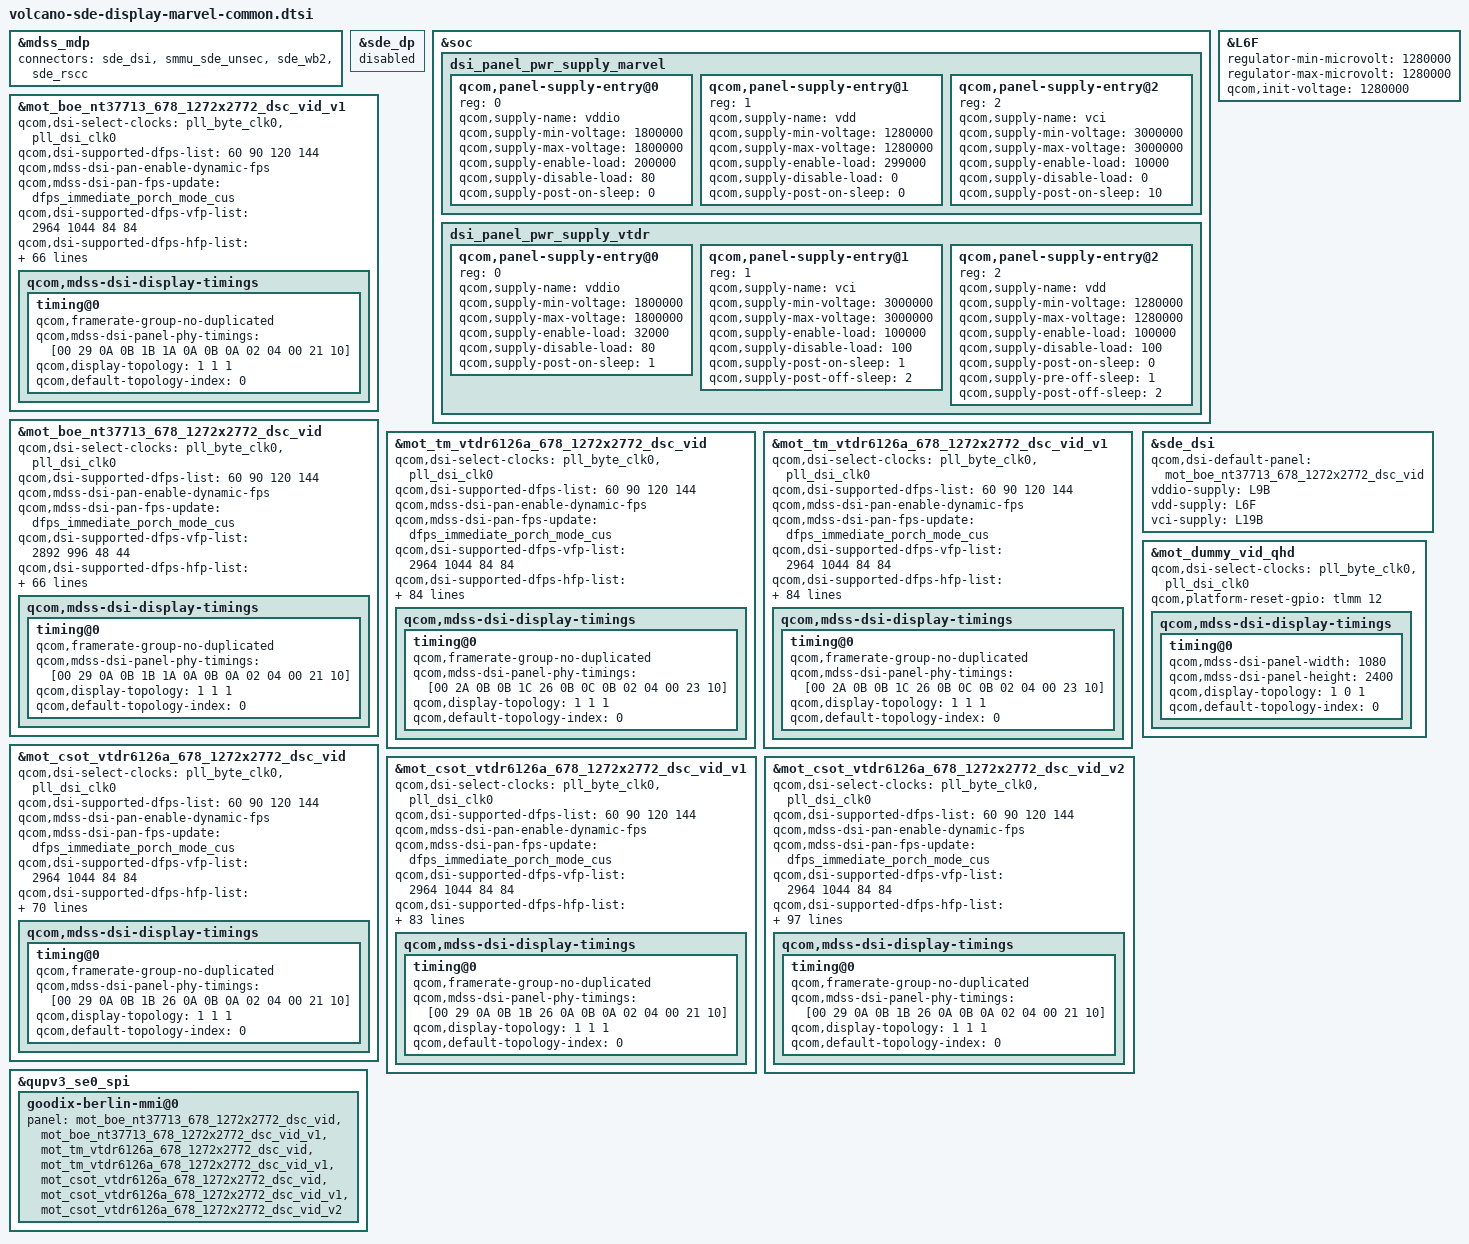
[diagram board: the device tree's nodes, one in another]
#include "volcano-sde-display.dtsi"
#include "dsi-panel-mot-dummy-qhd-video.dtsi"
#include "dsi-panel-mot-boe-nt37713-678_1272x2772-dsc-video-144hz-common.dtsi"
#include "dsi-panel-mot-boe-nt37713-678_1272x2772-dsc-video-144hz-common-v1.dtsi"
#include "dsi-panel-mot-tm-vtdr6126a-678_1272x2772-dsc-video-144hz-common.dtsi"
#include "dsi-panel-mot-tm-vtdr6126a-678_1272x2772-dsc-video-144hz-common-lhbm.dtsi"
#include "dsi-panel-mot-tm-vtdr6126a-678_1272x2772-dsc-video-144hz-common_v1.dtsi"
#include "dsi-panel-mot-tm-vtdr6126a-678_1272x2772-dsc-video-144hz-common-lhbm-v1.dtsi"
#include "dsi-panel-mot-csot-vtdr6126a-678_1272x2772-dsc-video-144hz-common.dtsi"
#include "dsi-panel-mot-csot-vtdr6126a-678_1272x2772-dsc-video-144hz-common-lhbm.dtsi"
#include "dsi-panel-mot-csot-vtdr6126a-678_1272x2772-dsc-video-144hz-common_v1.dtsi"
#include "dsi-panel-mot-csot-vtdr6126a-678_1272x2772-dsc-video-144hz-common-lhbm-v1.dtsi"
#include "dsi-panel-mot-csot-vtdr6126a-678_1272x2772-dsc-video-144hz-common_v2.dtsi"
#include "dsi-panel-mot-csot-vtdr6126a-678_1272x2772-dsc-video-144hz-common-lhbm-v2.dtsi"

&mdss_mdp {
	connectors = <&sde_dsi &smmu_sde_unsec &sde_wb2 &sde_rscc>;
};

&sde_dp {
	status = "disabled";
};

&soc {
	dsi_panel_pwr_supply_marvel: dsi_panel_pwr_supply_marvel {
		#address-cells = <1>;
		#size-cells = <0>;

		qcom,panel-supply-entry@0 {
			reg = <0>;
			qcom,supply-name = "vddio";
			qcom,supply-min-voltage = <1800000>;
			qcom,supply-max-voltage = <1800000>;
			qcom,supply-enable-load = <200000>;
			qcom,supply-disable-load = <80>;
			qcom,supply-post-on-sleep = <0>;
		};

		qcom,panel-supply-entry@1 {
			reg = <1>;
			qcom,supply-name = "vdd";
			qcom,supply-min-voltage = <1280000>;
			qcom,supply-max-voltage = <1280000>;
			qcom,supply-enable-load = <299000>;
			qcom,supply-disable-load = <0>;
			qcom,supply-post-on-sleep = <0>;
		};

		qcom,panel-supply-entry@2 {
			reg = <2>;
			qcom,supply-name = "vci";
			qcom,supply-min-voltage = <3000000>;
			qcom,supply-max-voltage = <3000000>;
			qcom,supply-enable-load = <10000>;
			qcom,supply-disable-load = <0>;
			qcom,supply-post-on-sleep = <10>;
		};
	};

	dsi_panel_pwr_supply_vtdr: dsi_panel_pwr_supply_vtdr {
		#address-cells = <1>;
		#size-cells = <0>;
		qcom,panel-supply-entry@0 {
			reg = <0>;
			qcom,supply-name = "vddio";
			qcom,supply-min-voltage = <1800000>;
			qcom,supply-max-voltage = <1800000>;
			qcom,supply-enable-load = <32000>;
			qcom,supply-disable-load = <80>;
			qcom,supply-post-on-sleep = <1>;
		};

		qcom,panel-supply-entry@1 {
			reg = <1>;
			qcom,supply-name = "vci";
			qcom,supply-min-voltage = <3000000>;
			qcom,supply-max-voltage = <3000000>;
			qcom,supply-enable-load = <100000>;
			qcom,supply-disable-load = <100>;
			qcom,supply-post-on-sleep = <1>;
			qcom,supply-post-off-sleep = <2>;
		};

		qcom,panel-supply-entry@2 {
			reg = <2>;
			qcom,supply-name = "vdd";
			qcom,supply-min-voltage = <1280000>;
			qcom,supply-max-voltage = <1280000>;
			qcom,supply-enable-load = <100000>;
			qcom,supply-disable-load = <100>;
			qcom,supply-post-on-sleep = <0>;
			qcom,supply-pre-off-sleep = <1>;
			qcom,supply-post-off-sleep = <2>;
		};
	};
};

&mot_boe_nt37713_678_1272x2772_dsc_vid_v1 {
	qcom,dsi-select-clocks = "pll_byte_clk0", "pll_dsi_clk0";

	qcom,dsi-supported-dfps-list = <60 90 120 144>;
	qcom,mdss-dsi-pan-enable-dynamic-fps;
	qcom,mdss-dsi-pan-fps-update = "dfps_immediate_porch_mode_cus";
	qcom,dsi-supported-dfps-vfp-list = <2964 1044 84 84>;
	qcom,dsi-supported-dfps-hfp-list = <108 108 108 28>;
	qcom,mdss-dsi-pan-dfps-send-command;
	qcom,dsi-supported-dfps-cmd-delay-effect-list = <144 120>;

	qcom,panel-supply-entries = <&dsi_panel_pwr_supply_marvel>;
	qcom,mdss-dsi-no-panel-on-read-support;
	qcom,mdss-dsi-bl-pmic-control-type = "bl_ctrl_dcs";
	qcom,mdss-dsi-bl-min-level = <420>;//
	qcom,mdss-dsi-bl-max-level = <16153>;
	qcom,mdss-dsi-bl-default-level = <6735>;
	qcom,mdss-brightness-max-level = <16153>;
	qcom,platform-reset-gpio = <&tlmm 12 0>;

	qcom,mdss-dsi-bl-inverted-dbv;
	qcom,mdss-dsi-bl-is-exponent;

	qcom,mdss-dsi-panel-hdr-enabled;//
	qcom,mdss-dsi-panel-hdr-color-primaries = <14950 15750 34000
	        16000 13000 35500 7000 2500>;
	qcom,mdss-dsi-panel-peak-brightness = <15000000>;
	qcom,mdss-dsi-panel-blackness-level = <1>;

	qcom,mdss-dsi-panel-status-check-mode = "reg_read";
	qcom,mdss-dsi-panel-status-command = [06 01 00 01 00 00 01 0A];
	qcom,mdss-dsi-panel-status-command-state = "dsi_lp_mode";
	qcom,mdss-dsi-panel-status-value = <0x9C>;
	qcom,mdss-dsi-panel-status-read-length = <1>;
	qcom,esd-check-enabled;

	qcom,cellid-read-enabled;//
	qcom,mdss-dsi-panel-cellid-read-length = <23>;
	qcom,mdss-dsi-panel-cellid-command = [06 01 00 01 00 00 01 AC];
	qcom,mdss-dsi-panel-cellid-command-state = "dsi_lp_mode";

	qcom,check_pcd;
	qcom,pcd-reg-read-enabled;
	qcom,pcd-reg-check-before-read;
	qcom,mdss-dsi-panel-pcd-reg-read-length = <3>;
	qcom,mdss-dsi-panel-pcd-reg-offset = <1>;
	qcom,mdss-dsi-panel-pcd-reg-mask = <0xFFFF>;
	qcom,mdss-dsi-panel-pcd-reg-command = [
		39 00 00 40 00 00 06 F0 55 AA 52 08 01
		06 01 00 01 00 00 01 D0];
	qcom,mdss-dsi-panel-pcd-value-2bytes;
	qcom,mdss-dsi-panel-pcd-reg-pass-min = <0x0200>;
	qcom,mdss-dsi-panel-pcd-reg-pass-max = <0x02C0>;
	qcom,mdss-dsi-panel-pcd-reg-read-delay-ms = <150>;
	qcom,mdss-dsi-panel-pcd-reg-seq-interval = <30>; //pcd reg read seq interval per screen on.
	qcom,mdss-dsi-panel-pcd-check-time-interval-in-minutes = <480>; //480 minutes/8hours for pcd reg read time interval

	// only parse for cmd panel
	qcom,mdss-dsi-te-pin-select = <1>;
	qcom,mdss-dsi-te-dcs-command = <1>;
	qcom,mdss-dsi-te-using-te-pin;
	qcom,mdss-dsi-te-check-enable;

	//AOD: config switch mode
	qcom,mdss-dsi-panel-mode-switch;
	//qcom,poms-align-panel-vsync;
	qcom,dynamic-mode-switch-enabled;
	//qcom,dynamic-mode-switch-type = "dynamic-switch-immediate";

	qcom,mdss-dsi-panel-AOD-config-enabled;
	qcom,mdss-dsi-panel-AOD-bl-vid-update;

	qcom,mdss-dsi-panel-AOD-THRESHOLD-min-nit = <1112>;	//5nit
	qcom,mdss-dsi-panel-AOD-THRESHOLD-hig-nit = <6735>;	//160nit

	qcom,mdss-dsi-panel-AOD-bl-min = <16>;   //0x0010, <5nit
	qcom,mdss-dsi-panel-AOD-bl-mid = <11344>;   //0x2C50, 5-160nit
	qcom,mdss-dsi-panel-AOD-bl-hig = <16000>;   //0x3E80, >160nit

	qcom,mdss-dsi-display-timings {
		timing@0 {
			qcom,framerate-group-no-duplicated;
			qcom,mdss-dsi-panel-phy-timings = [00 29 0A 0B 1B 1A 0A
				0B 0A 02 04 00 21 10];
			qcom,display-topology = <1 1 1>;
			qcom,default-topology-index = <0>;
		};
	};
};

&mot_boe_nt37713_678_1272x2772_dsc_vid {
	qcom,dsi-select-clocks = "pll_byte_clk0", "pll_dsi_clk0";

	qcom,dsi-supported-dfps-list = <60 90 120 144>;
	qcom,mdss-dsi-pan-enable-dynamic-fps;
	qcom,mdss-dsi-pan-fps-update = "dfps_immediate_porch_mode_cus";
	qcom,dsi-supported-dfps-vfp-list = <2892 996 48 44>;
	qcom,dsi-supported-dfps-hfp-list = <108 108 108 28>;
	qcom,mdss-dsi-pan-dfps-send-command;
	qcom,dsi-supported-dfps-cmd-delay-effect-list = <144 120>;

	qcom,panel-supply-entries = <&dsi_panel_pwr_supply_marvel>;
	qcom,mdss-dsi-no-panel-on-read-support;
	qcom,mdss-dsi-bl-pmic-control-type = "bl_ctrl_dcs";
	qcom,mdss-dsi-bl-min-level = <420>;//
	qcom,mdss-dsi-bl-max-level = <16153>;
	qcom,mdss-dsi-bl-default-level = <6735>;
	qcom,mdss-brightness-max-level = <16153>;
	qcom,platform-reset-gpio = <&tlmm 12 0>;

	qcom,mdss-dsi-bl-inverted-dbv;
	qcom,mdss-dsi-bl-is-exponent;

	qcom,mdss-dsi-panel-hdr-enabled;//
	qcom,mdss-dsi-panel-hdr-color-primaries = <14950 15750 34000
	        16000 13000 35500 7000 2500>;
	qcom,mdss-dsi-panel-peak-brightness = <15000000>;
	qcom,mdss-dsi-panel-blackness-level = <1>;

	qcom,mdss-dsi-panel-status-check-mode = "reg_read";
	qcom,mdss-dsi-panel-status-command = [06 01 00 01 00 00 01 0A];
	qcom,mdss-dsi-panel-status-command-state = "dsi_lp_mode";
	qcom,mdss-dsi-panel-status-value = <0x9C>;
	qcom,mdss-dsi-panel-status-read-length = <1>;
	qcom,esd-check-enabled;

	qcom,cellid-read-enabled;//
	qcom,mdss-dsi-panel-cellid-read-length = <23>;
	qcom,mdss-dsi-panel-cellid-command = [06 01 00 01 00 00 01 AC];
	qcom,mdss-dsi-panel-cellid-command-state = "dsi_lp_mode";

	qcom,check_pcd;
	qcom,pcd-reg-read-enabled;
	qcom,pcd-reg-check-before-read;
	qcom,mdss-dsi-panel-pcd-reg-read-length = <3>;
	qcom,mdss-dsi-panel-pcd-reg-offset = <1>;
	qcom,mdss-dsi-panel-pcd-reg-mask = <0xFFFF>;
	qcom,mdss-dsi-panel-pcd-reg-command = [
		39 00 00 40 00 00 06 F0 55 AA 52 08 01
		06 01 00 01 00 00 01 D0];
	qcom,mdss-dsi-panel-pcd-value-2bytes;
	qcom,mdss-dsi-panel-pcd-reg-pass-min = <0x0200>;
	qcom,mdss-dsi-panel-pcd-reg-pass-max = <0x02C0>;
	qcom,mdss-dsi-panel-pcd-reg-read-delay-ms = <150>;
	qcom,mdss-dsi-panel-pcd-reg-seq-interval = <30>; //pcd reg read seq interval per screen on.
	qcom,mdss-dsi-panel-pcd-check-time-interval-in-minutes = <480>; //480 minutes/8hours for pcd reg read time interval

	// only parse for cmd panel
	qcom,mdss-dsi-te-pin-select = <1>;
	qcom,mdss-dsi-te-dcs-command = <1>;
	qcom,mdss-dsi-te-using-te-pin;
	qcom,mdss-dsi-te-check-enable;

	//AOD: config switch mode
	qcom,mdss-dsi-panel-mode-switch;
	//qcom,poms-align-panel-vsync;
	qcom,dynamic-mode-switch-enabled;
	//qcom,dynamic-mode-switch-type = "dynamic-switch-immediate";

	qcom,mdss-dsi-panel-AOD-config-enabled;
	qcom,mdss-dsi-panel-AOD-bl-vid-update;

	qcom,mdss-dsi-panel-AOD-THRESHOLD-min-nit = <1112>;	//5nit
	qcom,mdss-dsi-panel-AOD-THRESHOLD-hig-nit = <6735>;	//160nit

	qcom,mdss-dsi-panel-AOD-bl-min = <16>;   //0x0010, <5nit
	qcom,mdss-dsi-panel-AOD-bl-mid = <11344>;   //0x2C50, 5-160nit
	qcom,mdss-dsi-panel-AOD-bl-hig = <16000>;   //0x3E80, >160nit

	qcom,mdss-dsi-display-timings {
		timing@0 {
			qcom,framerate-group-no-duplicated;
			qcom,mdss-dsi-panel-phy-timings = [00 29 0A 0B 1B 1A 0A
				0B 0A 02 04 00 21 10];
			qcom,display-topology = <1 1 1>;
			qcom,default-topology-index = <0>;
		};
	};
};

&mot_tm_vtdr6126a_678_1272x2772_dsc_vid {
	qcom,dsi-select-clocks = "pll_byte_clk0", "pll_dsi_clk0";

	qcom,dsi-supported-dfps-list = <60 90 120 144>;
	qcom,mdss-dsi-pan-enable-dynamic-fps;
	qcom,mdss-dsi-pan-fps-update = "dfps_immediate_porch_mode_cus";
	qcom,dsi-supported-dfps-vfp-list = <2964 1044 84 84>;
	qcom,dsi-supported-dfps-hfp-list = <124 124 124 40>;
	qcom,mdss-dsi-pan-dfps-send-command;
	qcom,dsi-supported-dfps-cmd-delay-effect-list = <144 120>;

	qcom,panel-supply-entries = <&dsi_panel_pwr_supply_vtdr>;
	qcom,mdss-dsi-no-panel-on-read-support;
	qcom,mdss-dsi-bl-pmic-control-type = "bl_ctrl_dcs";
	qcom,mdss-dsi-bl-min-level = <420>;
	qcom,mdss-dsi-bl-max-level = <16153>;
	qcom,mdss-dsi-bl-default-level = <6735>;
	qcom,mdss-brightness-max-level = <16153>;
	qcom,platform-reset-gpio = <&tlmm 12 0>;

	qcom,mdss-dsi-bl-inverted-dbv;
	qcom,mdss-dsi-bl-is-exponent;

	qcom,mdss-dsi-panel-hdr-enabled;
	qcom,mdss-dsi-panel-hdr-color-primaries = <14950 15750 34000
	        16000 13000 35500 7000 2500>;
	qcom,mdss-dsi-panel-peak-brightness = <15000000>;
	qcom,mdss-dsi-panel-blackness-level = <1>;

	qcom,mdss-dsi-panel-status-check-mode = "reg_read";
	qcom,mdss-dsi-panel-status-command = [06 01 00 01 00 00 01 0A
					      06 01 00 01 00 00 01 66];
	qcom,mdss-dsi-panel-status-command-state = "dsi_hs_mode";
	qcom,mdss-dsi-panel-status-value = <0x9C 0x00 0x00>;
	qcom,mdss-dsi-panel-status-read-length = <1 2>;
	qcom,esd-check-enabled;

	qcom,cellid-read-enabled;
	qcom,mdss-dsi-panel-cellid-read-length = <23>;
	qcom,mdss-dsi-panel-cellid-command = [06 01 00 01 00 00 01 5A];
	qcom,mdss-dsi-panel-cellid-command-state = "dsi_hs_mode";

	qcom,check_pcd;
	qcom,pcd-reg-read-enabled;
	qcom,pcd-reg-check-before-read;
	qcom,mdss-dsi-panel-pcd-reg-read-length = <1>;
	qcom,mdss-dsi-panel-pcd-reg-mask = <0xFF>;
	qcom,mdss-dsi-panel-pcd-reg-command = [
		39 00 00 40 00 00 03 F0 AA 12
		39 00 00 00 00 00 02 65 04
		06 01 00 01 00 00 01 D0];
	qcom,mdss-dsi-panel-pcd-reg-command-state = "dsi_hs_mode";
	qcom,mdss-dsi-panel-pcd-reg-pass-min = <0x90>;
	qcom,mdss-dsi-panel-pcd-reg-pass-max = <0xDC>;
	qcom,mdss-dsi-panel-pcd-reg-read-delay-ms = <150>; //150ms delay before read pcd reg per IC req
	qcom,mdss-dsi-panel-pcd-reg-seq-interval = <30>; //30 seq interval per screen on times
	qcom,mdss-dsi-panel-pcd-check-time-interval-in-minutes = <480>; //480 minutes/8hours for pcd reg read time interval
	qcom,mdss-dsi-panel-pcd-value-zero_valid; //avoid vtdr6126a pcd read not on D0 lane lp11 state

	// only parse for cmd panel
	qcom,mdss-dsi-te-pin-select = <1>;
	qcom,mdss-dsi-te-dcs-command = <1>;
	qcom,mdss-dsi-te-using-te-pin;
	qcom,mdss-dsi-te-check-enable;
	qcom,mdss-dsi-wr-mem-start = <0x2c>;
	qcom,mdss-dsi-wr-mem-continue = <0x3c>;

	//AOD: config switch mode
	qcom,mdss-dsi-panel-mode-switch;
	//qcom,poms-align-panel-vsync;
	qcom,dynamic-mode-switch-enabled;
	//qcom,dynamic-mode-switch-type = "dynamic-switch-immediate";

	qcom,mdss-dsi-panel-AOD-config-enabled;
	qcom,mdss-dsi-panel-AOD-bl-vid-update;

	qcom,mdss-dsi-panel-AOD-THRESHOLD-min-nit = <1112>;	//5nit
	qcom,mdss-dsi-panel-AOD-THRESHOLD-hig-nit = <6735>;	//160nit

	qcom,mdss-dsi-panel-AOD-bl-min = <0>; //5nit
	qcom,mdss-dsi-panel-AOD-bl-mid = <1>; //60nit
	qcom,mdss-dsi-panel-AOD-bl-hig = <2>; //160nit

	qcom,panel-od-enabled;
	qcom,panel-od-bypass-in-cmd;
	qcom,mdss-dsi-panel-od-reg = <0xC0>;
	qcom,mdss-dsi-panel-od-on-val = <0xA0>;
	qcom,mdss-dsi-panel-od-off-val = <0x00>;
	qcom,mdss-dsi-bl-od-threshold = <2168>;
	qcom,mdss-dsi-panel-od-on-command = [
		39 00 00 40 00 00 02 A4 01
		39 00 00 40 00 00 03 F0 AA 19
		39 00 00 40 00 00 02 C0 A0
		39 00 00 40 00 00 03 51 03 6E
		39 00 00 40 00 00 03 F0 AA 00
		39 00 00 40 00 00 02 A4 00
		39 00 00 00 00 00 02 A6 01];
	qcom,mdss-dsi-panel-od-on-command-state = "dsi_hs_mode";
	qcom,mdss-dsi-panel-od-off-command = [
		39 00 00 40 00 00 02 A4 01
		39 00 00 40 00 00 03 F0 AA 19
		39 00 00 40 00 00 02 C0 00
		39 00 00 40 00 00 03 51 03 6E
		39 00 00 40 00 00 03 F0 AA 00
		39 00 00 40 00 00 02 A4 00
		39 00 00 00 00 00 02 A6 01];
	qcom,mdss-dsi-panel-od-off-command-state = "dsi_hs_mode";

	qcom,mdss-dsi-display-timings {
		timing@0 {
			qcom,framerate-group-no-duplicated;
			//qcom,mdss-dsi-panel-clockrate = <1095000000>;
			qcom,mdss-dsi-panel-phy-timings = [00 2A 0B 0B 1C 26 0B
				0C 0B 02 04 00 23 10];
			qcom,display-topology = <1 1 1>;
			qcom,default-topology-index = <0>;
		};
	};
};

&mot_tm_vtdr6126a_678_1272x2772_dsc_vid_v1 {
	qcom,dsi-select-clocks = "pll_byte_clk0", "pll_dsi_clk0";

	qcom,dsi-supported-dfps-list = <60 90 120 144>;
	qcom,mdss-dsi-pan-enable-dynamic-fps;
	qcom,mdss-dsi-pan-fps-update = "dfps_immediate_porch_mode_cus";
	qcom,dsi-supported-dfps-vfp-list = <2964 1044 84 84>;
	qcom,dsi-supported-dfps-hfp-list = <124 124 124 40>;
	qcom,mdss-dsi-pan-dfps-send-command;
	qcom,dsi-supported-dfps-cmd-delay-effect-list = <144 120>;

	qcom,panel-supply-entries = <&dsi_panel_pwr_supply_vtdr>;
	qcom,mdss-dsi-no-panel-on-read-support;
	qcom,mdss-dsi-bl-pmic-control-type = "bl_ctrl_dcs";
	qcom,mdss-dsi-bl-min-level = <420>;
	qcom,mdss-dsi-bl-max-level = <16153>;
	qcom,mdss-dsi-bl-default-level = <6735>;
	qcom,mdss-brightness-max-level = <16153>;
	qcom,platform-reset-gpio = <&tlmm 12 0>;

	qcom,mdss-dsi-bl-inverted-dbv;
	qcom,mdss-dsi-bl-is-exponent;

	qcom,mdss-dsi-panel-hdr-enabled;
	qcom,mdss-dsi-panel-hdr-color-primaries = <14950 15750 34000
	        16000 13000 35500 7000 2500>;
	qcom,mdss-dsi-panel-peak-brightness = <15000000>;
	qcom,mdss-dsi-panel-blackness-level = <1>;

	qcom,mdss-dsi-panel-status-check-mode = "reg_read";
	qcom,mdss-dsi-panel-status-command = [06 01 00 01 00 00 01 0A
					      06 01 00 01 00 00 01 66];
	qcom,mdss-dsi-panel-status-command-state = "dsi_hs_mode";
	qcom,mdss-dsi-panel-status-value = <0x9C 0x00 0x00>;
	qcom,mdss-dsi-panel-status-read-length = <1 2>;
	qcom,esd-check-enabled;

	qcom,cellid-read-enabled;
	qcom,mdss-dsi-panel-cellid-read-length = <23>;
	qcom,mdss-dsi-panel-cellid-command = [06 01 00 01 00 00 01 5A];
	qcom,mdss-dsi-panel-cellid-command-state = "dsi_hs_mode";

	qcom,check_pcd;
	qcom,pcd-reg-read-enabled;
	qcom,pcd-reg-check-before-read;
	qcom,mdss-dsi-panel-pcd-reg-read-length = <1>;
	qcom,mdss-dsi-panel-pcd-reg-mask = <0xFF>;
	qcom,mdss-dsi-panel-pcd-reg-command = [
		39 00 00 40 00 00 03 F0 AA 12
		39 00 00 00 00 00 02 65 04
		06 01 00 01 00 00 01 D0];
	qcom,mdss-dsi-panel-pcd-reg-command-state = "dsi_hs_mode";
	qcom,mdss-dsi-panel-pcd-reg-pass-min = <0x90>;
	qcom,mdss-dsi-panel-pcd-reg-pass-max = <0xDC>;
	qcom,mdss-dsi-panel-pcd-reg-read-delay-ms = <150>; //150ms delay before read pcd reg per IC req
	qcom,mdss-dsi-panel-pcd-reg-seq-interval = <30>; //30 seq interval per screen on times
	qcom,mdss-dsi-panel-pcd-check-time-interval-in-minutes = <480>; //480 minutes/8hours for pcd reg read time interval
	qcom,mdss-dsi-panel-pcd-value-zero_valid; //avoid vtdr6126a pcd read not on D0 lane lp11 state

	// only parse for cmd panel
	qcom,mdss-dsi-te-pin-select = <1>;
	qcom,mdss-dsi-te-dcs-command = <1>;
	qcom,mdss-dsi-te-using-te-pin;
	qcom,mdss-dsi-te-check-enable;
	qcom,mdss-dsi-wr-mem-start = <0x2c>;
	qcom,mdss-dsi-wr-mem-continue = <0x3c>;

	//AOD: config switch mode
	qcom,mdss-dsi-panel-mode-switch;
	//qcom,poms-align-panel-vsync;
	qcom,dynamic-mode-switch-enabled;
	//qcom,dynamic-mode-switch-type = "dynamic-switch-immediate";

	qcom,mdss-dsi-panel-AOD-config-enabled;
	qcom,mdss-dsi-panel-AOD-bl-vid-update;

	qcom,mdss-dsi-panel-AOD-THRESHOLD-min-nit = <1112>;	//5nit
	qcom,mdss-dsi-panel-AOD-THRESHOLD-hig-nit = <6735>;	//160nit

	qcom,mdss-dsi-panel-AOD-bl-min = <0>; //5nit
	qcom,mdss-dsi-panel-AOD-bl-mid = <1>; //60nit
	qcom,mdss-dsi-panel-AOD-bl-hig = <2>; //160nit

	qcom,panel-od-enabled;
	qcom,panel-od-bypass-in-cmd;
	qcom,mdss-dsi-panel-od-reg = <0xC0>;
	qcom,mdss-dsi-panel-od-on-val = <0xA0>;
	qcom,mdss-dsi-panel-od-off-val = <0x00>;
	qcom,mdss-dsi-bl-od-threshold = <2168>;
	qcom,mdss-dsi-panel-od-on-command = [
		39 00 00 40 00 00 02 A4 01
		39 00 00 40 00 00 03 F0 AA 19
		39 00 00 40 00 00 02 C0 A0
		39 00 00 40 00 00 03 51 03 6E
		39 00 00 40 00 00 03 F0 AA 00
		39 00 00 40 00 00 02 A4 00
		39 00 00 00 00 00 02 A6 01];
	qcom,mdss-dsi-panel-od-on-command-state = "dsi_hs_mode";
	qcom,mdss-dsi-panel-od-off-command = [
		39 00 00 40 00 00 02 A4 01
		39 00 00 40 00 00 03 F0 AA 19
		39 00 00 40 00 00 02 C0 00
		39 00 00 40 00 00 03 51 03 6E
		39 00 00 40 00 00 03 F0 AA 00
		39 00 00 40 00 00 02 A4 00
		39 00 00 00 00 00 02 A6 01];
	qcom,mdss-dsi-panel-od-off-command-state = "dsi_hs_mode";

	qcom,mdss-dsi-display-timings {
		timing@0 {
			qcom,framerate-group-no-duplicated;
			//qcom,mdss-dsi-panel-clockrate = <1095000000>;
			qcom,mdss-dsi-panel-phy-timings = [00 2A 0B 0B 1C 26 0B
				0C 0B 02 04 00 23 10];
			qcom,display-topology = <1 1 1>;
			qcom,default-topology-index = <0>;
		};
	};
};

&mot_csot_vtdr6126a_678_1272x2772_dsc_vid {
	qcom,dsi-select-clocks = "pll_byte_clk0", "pll_dsi_clk0";

	qcom,dsi-supported-dfps-list = <60 90 120 144>;
	qcom,mdss-dsi-pan-enable-dynamic-fps;
	qcom,mdss-dsi-pan-fps-update = "dfps_immediate_porch_mode_cus";
	qcom,dsi-supported-dfps-vfp-list = <2964 1044 84 84>;
	qcom,dsi-supported-dfps-hfp-list = <108 108 108 28>;
	qcom,mdss-dsi-pan-dfps-send-command;
	qcom,dsi-supported-dfps-cmd-delay-effect-list = <144 120>;

	qcom,panel-supply-entries = <&dsi_panel_pwr_supply_vtdr>;
	qcom,mdss-dsi-no-panel-on-read-support;
	qcom,mdss-dsi-bl-pmic-control-type = "bl_ctrl_dcs";
	qcom,mdss-dsi-bl-min-level = <420>;
	qcom,mdss-dsi-bl-max-level = <16153>;
	qcom,mdss-dsi-bl-default-level = <6735>;
	qcom,mdss-brightness-max-level = <16153>;
	qcom,platform-reset-gpio = <&tlmm 12 0>;

	qcom,mdss-dsi-bl-inverted-dbv;
	qcom,mdss-dsi-bl-is-exponent;

	qcom,mdss-dsi-panel-hdr-enabled;
	qcom,mdss-dsi-panel-hdr-color-primaries = <14950 15750 34000
	        16000 13000 35500 7000 2500>;
	qcom,mdss-dsi-panel-peak-brightness = <15000000>;
	qcom,mdss-dsi-panel-blackness-level = <1>;

	qcom,mdss-dsi-panel-status-check-mode = "reg_read";
	qcom,mdss-dsi-panel-status-command = [06 01 00 01 00 00 01 0A
					      06 01 00 01 00 00 01 66];
	qcom,mdss-dsi-panel-status-command-state = "dsi_hs_mode";
	qcom,mdss-dsi-panel-status-value = <0x9C 0x00 0x00>;
	qcom,mdss-dsi-panel-status-read-length = <1 2>;
	qcom,esd-check-enabled;

	qcom,cellid-read-enabled;
	qcom,mdss-dsi-panel-cellid-read-length = <23>;
	qcom,mdss-dsi-panel-cellid-command = [06 01 00 01 00 00 01 5A];
	qcom,mdss-dsi-panel-cellid-command-state = "dsi_hs_mode";

	qcom,check_pcd;
	qcom,pcd-reg-read-enabled;
	qcom,pcd-reg-check-before-read;
	qcom,mdss-dsi-panel-pcd-reg-read-length = <1>;
	qcom,mdss-dsi-panel-pcd-reg-mask = <0xFF>;
	qcom,mdss-dsi-panel-pcd-reg-command = [
		39 00 00 40 00 00 03 F0 AA 12
		39 00 00 00 00 00 02 65 04
		06 01 00 01 00 00 01 D0];
	qcom,mdss-dsi-panel-pcd-reg-command-state = "dsi_hs_mode";
	qcom,mdss-dsi-panel-pcd-reg-pass-min = <0x80>;
	qcom,mdss-dsi-panel-pcd-reg-pass-max = <0x85>;
	qcom,mdss-dsi-panel-pcd-reg-read-delay-ms = <150>; //150ms delay before read pcd reg per IC req
	qcom,mdss-dsi-panel-pcd-reg-seq-interval = <30>; //30 seq interval per screen on times
	qcom,mdss-dsi-panel-pcd-check-time-interval-in-minutes = <480>; //480 minutes/8hours for pcd reg read time interval
	qcom,mdss-dsi-panel-pcd-value-zero_valid; //avoid vtdr6126a pcd read not on D0 lane lp11 state

	// only parse for cmd panel
	qcom,mdss-dsi-te-pin-select = <1>;
	qcom,mdss-dsi-te-dcs-command = <1>;
	qcom,mdss-dsi-te-using-te-pin;
	qcom,mdss-dsi-te-check-enable;
	qcom,mdss-dsi-wr-mem-start = <0x2c>;
	qcom,mdss-dsi-wr-mem-continue = <0x3c>;

	//AOD: config switch mode
	qcom,mdss-dsi-panel-mode-switch;
	//qcom,poms-align-panel-vsync;
	qcom,dynamic-mode-switch-enabled;
	//qcom,dynamic-mode-switch-type = "dynamic-switch-immediate";

	qcom,mdss-dsi-panel-AOD-config-enabled;
	qcom,mdss-dsi-panel-AOD-bl-vid-update;

	qcom,mdss-dsi-panel-AOD-THRESHOLD-min-nit = <1112>;	//5nit
	qcom,mdss-dsi-panel-AOD-THRESHOLD-hig-nit = <6735>;	//160nit

	qcom,mdss-dsi-panel-AOD-bl-min = <2>; //5nit
	qcom,mdss-dsi-panel-AOD-bl-mid = <1>; //60nit
	qcom,mdss-dsi-panel-AOD-bl-hig = <0>; //160nit

	qcom,mdss-dsi-display-timings {
		timing@0 {
			qcom,framerate-group-no-duplicated;
			//qcom,mdss-dsi-panel-clockrate = <1095000000>;
			qcom,mdss-dsi-panel-phy-timings = [00 29 0A 0B 1B 26 0A
				0B 0A 02 04 00 21 10];
			qcom,display-topology = <1 1 1>;
			qcom,default-topology-index = <0>;
		};
	};
};

&mot_csot_vtdr6126a_678_1272x2772_dsc_vid_v1 {
	qcom,dsi-select-clocks = "pll_byte_clk0", "pll_dsi_clk0";

	qcom,dsi-supported-dfps-list = <60 90 120 144>;
	qcom,mdss-dsi-pan-enable-dynamic-fps;
	qcom,mdss-dsi-pan-fps-update = "dfps_immediate_porch_mode_cus";
	qcom,dsi-supported-dfps-vfp-list = <2964 1044 84 84>;
	qcom,dsi-supported-dfps-hfp-list = <108 108 108 28>;
	qcom,mdss-dsi-pan-dfps-send-command;
	qcom,dsi-supported-dfps-cmd-delay-effect-list = <144 120>;

	qcom,panel-supply-entries = <&dsi_panel_pwr_supply_vtdr>;
	qcom,mdss-dsi-no-panel-on-read-support;
	qcom,mdss-dsi-bl-pmic-control-type = "bl_ctrl_dcs";
	qcom,mdss-dsi-bl-min-level = <420>;
	qcom,mdss-dsi-bl-max-level = <16153>;
	qcom,mdss-dsi-bl-default-level = <6735>;
	qcom,mdss-brightness-max-level = <16153>;
	qcom,platform-reset-gpio = <&tlmm 12 0>;

	qcom,mdss-dsi-bl-inverted-dbv;
	qcom,mdss-dsi-bl-is-exponent;

	qcom,mdss-dsi-panel-hdr-enabled;
	qcom,mdss-dsi-panel-hdr-color-primaries = <14950 15750 34000
	        16000 13000 35500 7000 2500>;
	qcom,mdss-dsi-panel-peak-brightness = <15000000>;
	qcom,mdss-dsi-panel-blackness-level = <1>;

	qcom,mdss-dsi-panel-status-check-mode = "reg_read";
	qcom,mdss-dsi-panel-status-command = [06 01 00 01 00 00 01 0A
					      06 01 00 01 00 00 01 66];
	qcom,mdss-dsi-panel-status-command-state = "dsi_hs_mode";
	qcom,mdss-dsi-panel-status-value = <0x9C 0x00 0x00>;
	qcom,mdss-dsi-panel-status-read-length = <1 2>;
	qcom,esd-check-enabled;

	qcom,cellid-read-enabled;
	qcom,mdss-dsi-panel-cellid-read-length = <23>;
	qcom,mdss-dsi-panel-cellid-command = [06 01 00 01 00 00 01 5A];
	qcom,mdss-dsi-panel-cellid-command-state = "dsi_hs_mode";

	qcom,check_pcd;
	qcom,pcd-reg-read-enabled;
	qcom,pcd-reg-check-before-read;
	qcom,mdss-dsi-panel-pcd-reg-read-length = <1>;
	qcom,mdss-dsi-panel-pcd-reg-mask = <0xFF>;
	qcom,mdss-dsi-panel-pcd-reg-command = [
		39 00 00 40 00 00 03 F0 AA 12
		39 00 00 00 00 00 02 65 04
		06 01 00 01 00 00 01 D0];
	qcom,mdss-dsi-panel-pcd-reg-command-state = "dsi_hs_mode";
	qcom,mdss-dsi-panel-pcd-reg-pass-min = <0x80>;
	qcom,mdss-dsi-panel-pcd-reg-pass-max = <0x85>;
	qcom,mdss-dsi-panel-pcd-reg-read-delay-ms = <150>; //150ms delay before read pcd reg per IC req
	qcom,mdss-dsi-panel-pcd-reg-seq-interval = <30>; //30 seq interval per screen on times
	qcom,mdss-dsi-panel-pcd-check-time-interval-in-minutes = <480>; //480 minutes/8hours for pcd reg read time interval
	qcom,mdss-dsi-panel-pcd-value-zero_valid; //avoid vtdr6126a pcd read not on D0 lane lp11 state

	// only parse for cmd panel
	qcom,mdss-dsi-te-pin-select = <1>;
	qcom,mdss-dsi-te-dcs-command = <1>;
	qcom,mdss-dsi-te-using-te-pin;
	qcom,mdss-dsi-te-check-enable;
	qcom,mdss-dsi-wr-mem-start = <0x2c>;
	qcom,mdss-dsi-wr-mem-continue = <0x3c>;

	//AOD: config switch mode
	qcom,mdss-dsi-panel-mode-switch;
	//qcom,poms-align-panel-vsync;
	qcom,dynamic-mode-switch-enabled;
	//qcom,dynamic-mode-switch-type = "dynamic-switch-immediate";

	qcom,mdss-dsi-panel-AOD-config-enabled;
	qcom,mdss-dsi-panel-AOD-bl-vid-update;

	qcom,mdss-dsi-panel-AOD-THRESHOLD-min-nit = <1112>;	//5nit
	qcom,mdss-dsi-panel-AOD-THRESHOLD-hig-nit = <6735>;	//160nit

	qcom,mdss-dsi-panel-AOD-bl-min = <2>; //5nit
	qcom,mdss-dsi-panel-AOD-bl-mid = <1>; //60nit
	qcom,mdss-dsi-panel-AOD-bl-hig = <0>; //160nit

	qcom,apl-enabled;
	qcom,mdss-dsi-panel-apl-with-backlight;
	qcom,mdss-dsi-panel-apl-bl-pos = <1>;
	qcom,mdss-dsi-panel-apl-reg = <0x51>;
	qcom,mdss-dsi-panel-APL-THRESHOLD-BL = <16000>;
	qcom,mdss-dsi-panel-apl-on-command = [
		39 00 00 40 00 00 03 F0 AA 11
		39 00 00 40 00 00 02 D5 10
		39 00 00 40 00 00 03 51 3E 80
		39 00 00 40 00 00 03 F0 AA 00
		39 00 00 00 00 00 03 FF 5A 00];
	qcom,mdss-dsi-panel-apl-on-command-state = "dsi_hs_mode";
	qcom,mdss-dsi-panel-apl-off-command = [
		39 00 00 40 00 00 03 F0 AA 11
		39 00 00 40 00 00 02 D5 13
		39 00 00 40 00 00 03 51 3E 80
		39 00 00 40 00 00 03 F0 AA 00
		39 00 00 00 00 00 03 FF 5A 00];
	qcom,mdss-dsi-panel-apl-off-command-state = "dsi_hs_mode";

	qcom,mdss-dsi-display-timings {
		timing@0 {
			qcom,framerate-group-no-duplicated;
			//qcom,mdss-dsi-panel-clockrate = <1095000000>;
			qcom,mdss-dsi-panel-phy-timings = [00 29 0A 0B 1B 26 0A
				0B 0A 02 04 00 21 10];
			qcom,display-topology = <1 1 1>;
			qcom,default-topology-index = <0>;
		};
	};
};

&mot_csot_vtdr6126a_678_1272x2772_dsc_vid_v2 {
	qcom,dsi-select-clocks = "pll_byte_clk0", "pll_dsi_clk0";

	qcom,dsi-supported-dfps-list = <60 90 120 144>;
	qcom,mdss-dsi-pan-enable-dynamic-fps;
	qcom,mdss-dsi-pan-fps-update = "dfps_immediate_porch_mode_cus";
	qcom,dsi-supported-dfps-vfp-list = <2964 1044 84 84>;
	qcom,dsi-supported-dfps-hfp-list = <108 108 108 28>;
	qcom,mdss-dsi-pan-dfps-send-command;
	qcom,dsi-supported-dfps-cmd-delay-effect-list = <144 120>;

	qcom,panel-supply-entries = <&dsi_panel_pwr_supply_vtdr>;
	qcom,mdss-dsi-no-panel-on-read-support;
	qcom,mdss-dsi-bl-pmic-control-type = "bl_ctrl_dcs";
	qcom,mdss-dsi-bl-min-level = <420>;
	qcom,mdss-dsi-bl-max-level = <16153>;
	qcom,mdss-dsi-bl-default-level = <6735>;
	qcom,mdss-brightness-max-level = <16153>;
	qcom,platform-reset-gpio = <&tlmm 12 0>;

	qcom,mdss-dsi-bl-inverted-dbv;
	qcom,mdss-dsi-bl-is-exponent;

	qcom,mdss-dsi-panel-hdr-enabled;
	qcom,mdss-dsi-panel-hdr-color-primaries = <14950 15750 34000
	        16000 13000 35500 7000 2500>;
	qcom,mdss-dsi-panel-peak-brightness = <15000000>;
	qcom,mdss-dsi-panel-blackness-level = <1>;

	qcom,mdss-dsi-panel-status-check-mode = "reg_read";
	qcom,mdss-dsi-panel-status-command = [06 01 00 01 00 00 01 0A
					      06 01 00 01 00 00 01 66];
	qcom,mdss-dsi-panel-status-command-state = "dsi_hs_mode";
	qcom,mdss-dsi-panel-status-value = <0x9C 0x00 0x00>;
	qcom,mdss-dsi-panel-status-read-length = <1 2>;
	qcom,esd-check-enabled;

	qcom,cellid-read-enabled;
	qcom,mdss-dsi-panel-cellid-read-length = <23>;
	qcom,mdss-dsi-panel-cellid-command = [06 01 00 01 00 00 01 5A];
	qcom,mdss-dsi-panel-cellid-command-state = "dsi_hs_mode";

	qcom,check_pcd;
	qcom,pcd-reg-read-enabled;
	qcom,pcd-reg-check-before-read;
	qcom,mdss-dsi-panel-pcd-reg-read-length = <1>;
	qcom,mdss-dsi-panel-pcd-reg-mask = <0xFF>;
	qcom,mdss-dsi-panel-pcd-reg-command = [
		39 00 00 40 00 00 03 F0 AA 12
		39 00 00 00 00 00 02 65 04
		06 01 00 01 00 00 01 D0];
	qcom,mdss-dsi-panel-pcd-reg-command-state = "dsi_hs_mode";
	qcom,mdss-dsi-panel-pcd-reg-pass-min = <0x80>;
	qcom,mdss-dsi-panel-pcd-reg-pass-max = <0x85>;
	qcom,mdss-dsi-panel-pcd-reg-read-delay-ms = <150>; //150ms delay before read pcd reg per IC req
	qcom,mdss-dsi-panel-pcd-reg-seq-interval = <30>; //30 seq interval per screen on times
	qcom,mdss-dsi-panel-pcd-check-time-interval-in-minutes = <480>; //480 minutes/8hours for pcd reg read time interval
	qcom,mdss-dsi-panel-pcd-value-zero_valid; //avoid vtdr6126a pcd read not on D0 lane lp11 state

	// only parse for cmd panel
	qcom,mdss-dsi-te-pin-select = <1>;
	qcom,mdss-dsi-te-dcs-command = <1>;
	qcom,mdss-dsi-te-using-te-pin;
	qcom,mdss-dsi-te-check-enable;
	qcom,mdss-dsi-wr-mem-start = <0x2c>;
	qcom,mdss-dsi-wr-mem-continue = <0x3c>;

	//AOD: config switch mode
	qcom,mdss-dsi-panel-mode-switch;
	//qcom,poms-align-panel-vsync;
	qcom,dynamic-mode-switch-enabled;
	//qcom,dynamic-mode-switch-type = "dynamic-switch-immediate";

	qcom,mdss-dsi-panel-AOD-config-enabled;
	qcom,mdss-dsi-panel-AOD-bl-vid-update;

	qcom,mdss-dsi-panel-AOD-THRESHOLD-min-nit = <1112>;	//5nit
	qcom,mdss-dsi-panel-AOD-THRESHOLD-hig-nit = <6735>;	//160nit

	qcom,mdss-dsi-panel-AOD-bl-min = <2>; //5nit
	qcom,mdss-dsi-panel-AOD-bl-mid = <1>; //60nit
	qcom,mdss-dsi-panel-AOD-bl-hig = <0>; //160nit

	qcom,apl-enabled;
	qcom,mdss-dsi-panel-apl-with-backlight;
	qcom,mdss-dsi-panel-apl-bl-pos = <1>;
	qcom,mdss-dsi-panel-apl-reg = <0x51>;
	qcom,mdss-dsi-panel-APL-THRESHOLD-BL = <16000>;
	qcom,mdss-dsi-panel-apl-on-command = [
		39 00 00 40 00 00 03 F0 AA 11
		39 00 00 40 00 00 02 D5 10
		39 00 00 40 00 00 03 51 3E 80
		39 00 00 40 00 00 03 F0 AA 00
		39 00 00 00 00 00 03 FF 5A 00];
	qcom,mdss-dsi-panel-apl-on-command-state = "dsi_hs_mode";
	qcom,mdss-dsi-panel-apl-off-command = [
		39 00 00 40 00 00 03 F0 AA 11
		39 00 00 40 00 00 02 D5 13
		39 00 00 40 00 00 03 51 3E 80
		39 00 00 40 00 00 03 F0 AA 00
		39 00 00 00 00 00 03 FF 5A 00];
	qcom,mdss-dsi-panel-apl-off-command-state = "dsi_hs_mode";

	qcom,panel-od-enabled;
	qcom,panel-od-bypass-in-cmd;
	qcom,mdss-dsi-panel-od-reg = <0xC0>;
	qcom,mdss-dsi-panel-od-on-val = <0xA2>;
	qcom,mdss-dsi-panel-od-off-val = <0x00>;
	qcom,mdss-dsi-bl-od-threshold = <2168>;
	qcom,mdss-dsi-panel-od-on-command = [
		39 00 00 40 00 00 02 A4 01
		39 00 00 40 00 00 03 F0 AA 19
		39 00 00 40 00 00 02 C0 A2
		39 00 00 40 00 00 03 51 03 6E
		39 00 00 40 00 00 03 F0 AA 00
		39 00 00 40 00 00 02 A4 00
		39 00 00 00 00 00 02 A6 01];
	qcom,mdss-dsi-panel-od-on-command-state = "dsi_hs_mode";
	qcom,mdss-dsi-panel-od-off-command = [
		39 00 00 40 00 00 02 A4 01
		39 00 00 40 00 00 03 F0 AA 19
		39 00 00 40 00 00 02 C0 00
		39 00 00 40 00 00 03 51 03 6E
		39 00 00 40 00 00 03 F0 AA 00
		39 00 00 40 00 00 02 A4 00
		39 00 00 00 00 00 02 A6 01];
	qcom,mdss-dsi-panel-od-off-command-state = "dsi_hs_mode";

	qcom,mdss-dsi-display-timings {
		timing@0 {
			qcom,framerate-group-no-duplicated;
			//qcom,mdss-dsi-panel-clockrate = <1095000000>;
			qcom,mdss-dsi-panel-phy-timings = [00 29 0A 0B 1B 26 0A
				0B 0A 02 04 00 21 10];
			qcom,display-topology = <1 1 1>;
			qcom,default-topology-index = <0>;
		};
	};
};

&L6F {
       regulator-min-microvolt = <1280000>;
       regulator-max-microvolt = <1280000>;
       qcom,init-voltage = <1280000>;
};

&sde_dsi {
	qcom,dsi-default-panel = <&mot_boe_nt37713_678_1272x2772_dsc_vid>;

	vddio-supply = <&L9B>;
	vdd-supply = <&L6F>;
	vci-supply = <&L19B>;
};

&mot_dummy_vid_qhd {
	qcom,dsi-select-clocks = "pll_byte_clk0", "pll_dsi_clk0";

	qcom,platform-reset-gpio = <&tlmm 12 0>;
	qcom,mdss-dsi-display-timings {
		timing@0{
			qcom,mdss-dsi-panel-width = <1080>;
			qcom,mdss-dsi-panel-height = <2400>;

			qcom,display-topology = <1 0 1>;
			qcom,default-topology-index = <0>;
		};
	};
};

&qupv3_se0_spi {
	goodix-berlin-mmi@0 {
		panel = <&mot_boe_nt37713_678_1272x2772_dsc_vid
			 &mot_boe_nt37713_678_1272x2772_dsc_vid_v1
			 &mot_tm_vtdr6126a_678_1272x2772_dsc_vid
			 &mot_tm_vtdr6126a_678_1272x2772_dsc_vid_v1
			 &mot_csot_vtdr6126a_678_1272x2772_dsc_vid
			 &mot_csot_vtdr6126a_678_1272x2772_dsc_vid_v1
			 &mot_csot_vtdr6126a_678_1272x2772_dsc_vid_v2>;
	};
};
